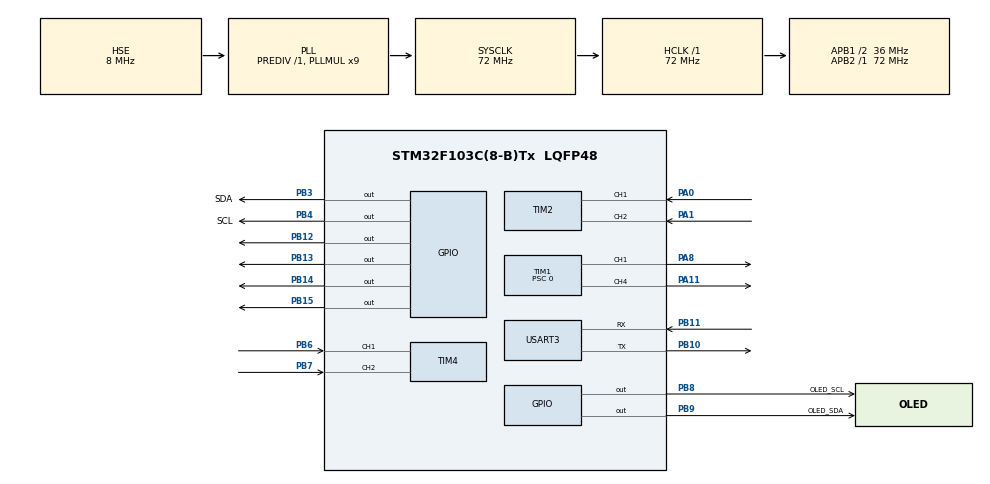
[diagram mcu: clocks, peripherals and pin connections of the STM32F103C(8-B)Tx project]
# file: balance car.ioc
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Mcu.Family=STM32F1
Mcu.Name=STM32F103C(8-B)Tx
Mcu.Package=LQFP48
NVIC.PriorityGroup=NVIC_PRIORITYGROUP_4
NVIC.TIM3_IRQn=true\:1\:0\:true\:false\:true\:false\:true\:true
NVIC.TimeBase=TIM3_IRQn
NVIC.TimeBaseIP=TIM3
NVIC.USART3_IRQn=true\:5\:0\:true\:false\:true\:true\:true\:true
PA0-WKUP.Signal=S_TIM2_CH1_ETR
PA1.Signal=S_TIM2_CH2
PA11.Signal=S_TIM1_CH4
PA13.Mode=Serial_Wire
PA13.Signal=SYS_JTMS-SWDIO
PA14.Mode=Serial_Wire
PA14.Signal=SYS_JTCK-SWCLK
PA8.Signal=S_TIM1_CH1
PB10.Mode=Asynchronous
PB10.Signal=USART3_TX
PB11.Mode=Asynchronous
PB11.Signal=USART3_RX
PB12.GPIO_ModeDefaultOutputPP=GPIO_MODE_OUTPUT_PP
PB12.GPIO_PuPd=GPIO_NOPULL
PB12.Signal=GPIO_Output
PB13.Signal=GPIO_Output
PB14.Signal=GPIO_Output
PB15.Signal=GPIO_Output
PB3.GPIO_Label=SDA
PB3.GPIO_ModeDefaultOutputPP=GPIO_MODE_OUTPUT_OD
PB3.GPIO_PuPd=GPIO_NOPULL
PB3.GPIO_Speed=GPIO_SPEED_FREQ_HIGH
PB3.PinState=GPIO_PIN_SET
PB3.Signal=GPIO_Output
PB4.GPIO_Label=SCL
PB4.GPIO_ModeDefaultOutputPP=GPIO_MODE_OUTPUT_OD
PB4.GPIO_PuPd=GPIO_NOPULL
PB4.GPIO_Speed=GPIO_SPEED_FREQ_HIGH
PB4.PinState=GPIO_PIN_SET
PB4.Signal=GPIO_Output
PB6.Signal=S_TIM4_CH1
PB7.Signal=S_TIM4_CH2
PB8.GPIO_Label=OLED_SCL
PB8.GPIO_ModeDefaultOutputPP=GPIO_MODE_OUTPUT_OD
PB8.GPIO_PuPd=GPIO_PULLUP
PB8.GPIO_Speed=GPIO_SPEED_FREQ_HIGH
PB8.PinState=GPIO_PIN_SET
PB8.Signal=GPIO_Output
PB9.GPIO_Label=OLED_SDA
PB9.GPIO_ModeDefaultOutputPP=GPIO_MODE_OUTPUT_OD
PB9.GPIO_PuPd=GPIO_PULLUP
PB9.GPIO_Speed=GPIO_SPEED_FREQ_HIGH
PB9.PinState=GPIO_PIN_SET
PB9.Signal=GPIO_Output
PD0-OSC_IN.Mode=HSE-External-Oscillator
PD0-OSC_IN.Signal=RCC_OSC_IN
PD1-OSC_OUT.Mode=HSE-External-Oscillator
PD1-OSC_OUT.Signal=RCC_OSC_OUT
ProjectManager.HeapSize=0x200
ProjectManager.StackSize=0x400
ProjectManager.TargetToolchain=MDK-ARM V5
RCC.AHBFreq_Value=72000000
RCC.APB1CLKDivider=RCC_HCLK_DIV2
RCC.APB1Freq_Value=36000000
RCC.APB1TimFreq_Value=72000000
RCC.APB2Freq_Value=72000000
RCC.APB2TimFreq_Value=72000000
RCC.HCLKFreq_Value=72000000
RCC.PLLMUL=RCC_PLL_MUL9
RCC.PLLSourceVirtual=RCC_PLLSOURCE_HSE
RCC.SYSCLKFreq_VALUE=72000000
RCC.SYSCLKSource=RCC_SYSCLKSOURCE_PLLCLK
RCC.USBFreq_Value=72000000
SH.S_TIM1_CH1.0=TIM1_CH1,PWM Generation1 CH1
SH.S_TIM1_CH4.0=TIM1_CH4,PWM Generation4 CH4
SH.S_TIM2_CH1_ETR.0=TIM2_CH1,Encoder_Interface
SH.S_TIM2_CH2.0=TIM2_CH2,Encoder_Interface
SH.S_TIM4_CH1.0=TIM4_CH1,Encoder_Interface
SH.S_TIM4_CH2.0=TIM4_CH2,Encoder_Interface
TIM1.Channel-PWM\ Generation1\ CH1=TIM_CHANNEL_1
TIM1.Channel-PWM\ Generation4\ CH4=TIM_CHANNEL_4
TIM1.Period=7200-1
TIM1.Prescaler=0
TIM2.EncoderMode=TIM_ENCODERMODE_TI12
TIM2.IC1Filter=10
TIM2.IC2Filter=10
TIM4.EncoderMode=TIM_ENCODERMODE_TI12
TIM4.IC1Filter=10
TIM4.IC2Filter=10
USART3.VirtualMode=VM_ASYNC
VP_SYS_VS_tim3.Mode=TIM3
VP_TIM1_VS_ClockSourceINT.Mode=Internal
board=custom

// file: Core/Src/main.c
/* USER CODE BEGIN Header */
/**
  ******************************************************************************
  * @file           : main.c
  * @brief          : Main program body
  ******************************************************************************
  * @attention
  *
  * Copyright (c) 2025 STMicroelectronics.
  * All rights reserved.
  *
  * This software is licensed under terms that can be found in the LICENSE file
  * in the root directory of this software component.
  * If no LICENSE file comes with this software, it is provided AS-IS.
  *
  ******************************************************************************
  */
/* USER CODE END Header */
#include "main.h"
#include "tim.h"
#include "usart.h"
#include "gpio.h"

/* USER CODE BEGIN Includes */
#include "OLED.h"
#include "MPU6050.h"
#include "CarTask.h"
/* USER CODE END Includes */

void SystemClock_Config(void);

int main(void)
{

  /* MCU Configuration--------------------------------------------------------*/

  /* Reset of all peripherals, Initializes the Flash interface and the Systick. */
  HAL_Init();

  /* Configure the system clock */
  SystemClock_Config();

  /* Initialize all configured peripherals */
  MX_GPIO_Init();
  MX_TIM1_Init();
  MX_TIM2_Init();
  MX_TIM4_Init();
  MX_USART3_UART_Init();
  /* USER CODE BEGIN 2 */

    OLED_Init();
    HAL_TIM_PWM_Start(&htim1, TIM_CHANNEL_1);
    HAL_TIM_PWM_Start(&htim1, TIM_CHANNEL_4);
    HAL_TIM_Encoder_Start(&htim2, TIM_CHANNEL_2);
    HAL_TIM_Encoder_Start(&htim2, TIM_CHANNEL_1);
    HAL_TIM_Encoder_Start(&htim4, TIM_CHANNEL_2);
    HAL_TIM_Encoder_Start(&htim4, TIM_CHANNEL_1);
    MPU6050_Init();

    Car_Init();

//    int16_t ax, ay, az, gx, gy, gz;
  /* USER CODE END 2 */

  /* Infinite loop */
  /* USER CODE BEGIN WHILE */
  while (1)
  {
//        MPU6050_GetCaliberateData(&ax, &ay, &az, &gx, &gy, &gz);
//      Get_Angle();
//      OLED_ShowSignedNum(1, 1 ,roll, 5);
//      OLED_ShowSignedNum(2, 1 ,pitch, 5);
//      OLED_ShowSignedNum(3, 1 ,yaw, 5);

//      Encoder_SpeedGet ();
////      printf("%d %d\r\n",EncoderL, EncoderR );
//      Delay_ms(200);
    /* USER CODE END WHILE */

  }
}

void SystemClock_Config(void)
{
  RCC_OscInitTypeDef RCC_OscInitStruct = {0};
  RCC_ClkInitTypeDef RCC_ClkInitStruct = {0};

  /** Initializes the RCC Oscillators according to the specified parameters
  * in the RCC_OscInitTypeDef structure.
  */
  RCC_OscInitStruct.OscillatorType = RCC_OSCILLATORTYPE_HSE;
  RCC_OscInitStruct.HSEState = RCC_HSE_ON;
  RCC_OscInitStruct.HSEPredivValue = RCC_HSE_PREDIV_DIV1;
  RCC_OscInitStruct.HSIState = RCC_HSI_ON;
  RCC_OscInitStruct.PLL.PLLState = RCC_PLL_ON;
  RCC_OscInitStruct.PLL.PLLSource = RCC_PLLSOURCE_HSE;
  RCC_OscInitStruct.PLL.PLLMUL = RCC_PLL_MUL9;
  if (HAL_RCC_OscConfig(&RCC_OscInitStruct) != HAL_OK)
  {
    Error_Handler();
  }

  /** Initializes the CPU, AHB and APB buses clocks
  */
  RCC_ClkInitStruct.ClockType = RCC_CLOCKTYPE_HCLK|RCC_CLOCKTYPE_SYSCLK
                              |RCC_CLOCKTYPE_PCLK1|RCC_CLOCKTYPE_PCLK2;
  RCC_ClkInitStruct.SYSCLKSource = RCC_SYSCLKSOURCE_PLLCLK;
  RCC_ClkInitStruct.AHBCLKDivider = RCC_SYSCLK_DIV1;
  RCC_ClkInitStruct.APB1CLKDivider = RCC_HCLK_DIV2;
  RCC_ClkInitStruct.APB2CLKDivider = RCC_HCLK_DIV1;

  if (HAL_RCC_ClockConfig(&RCC_ClkInitStruct, FLASH_LATENCY_2) != HAL_OK)
  {
    Error_Handler();
  }
}

void HAL_TIM_PeriodElapsedCallback(TIM_HandleTypeDef *htim)
{
  if (htim->Instance == TIM3)
  {
    HAL_IncTick();
  }
}

void Error_Handler(void)
{
  __disable_irq();
  while (1)
  {
  }
}
